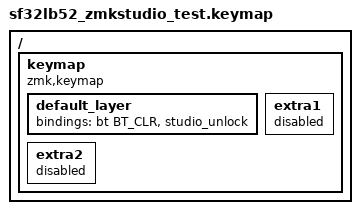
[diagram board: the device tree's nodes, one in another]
#define ZMK_BEHAVIORS_KEEP_ALL

#include <behaviors.dtsi>
#include <dt-bindings/zmk/keys.h>
#include <dt-bindings/zmk/bt.h>

/ {
	keymap {
		compatible = "zmk,keymap";

		default_layer {
			bindings = <
				&bt BT_CLR  &studio_unlock
			>;
		};

		extra1 {
			status = "reserved";
		};

		extra2 {
			status = "reserved";
		};
	};
};
